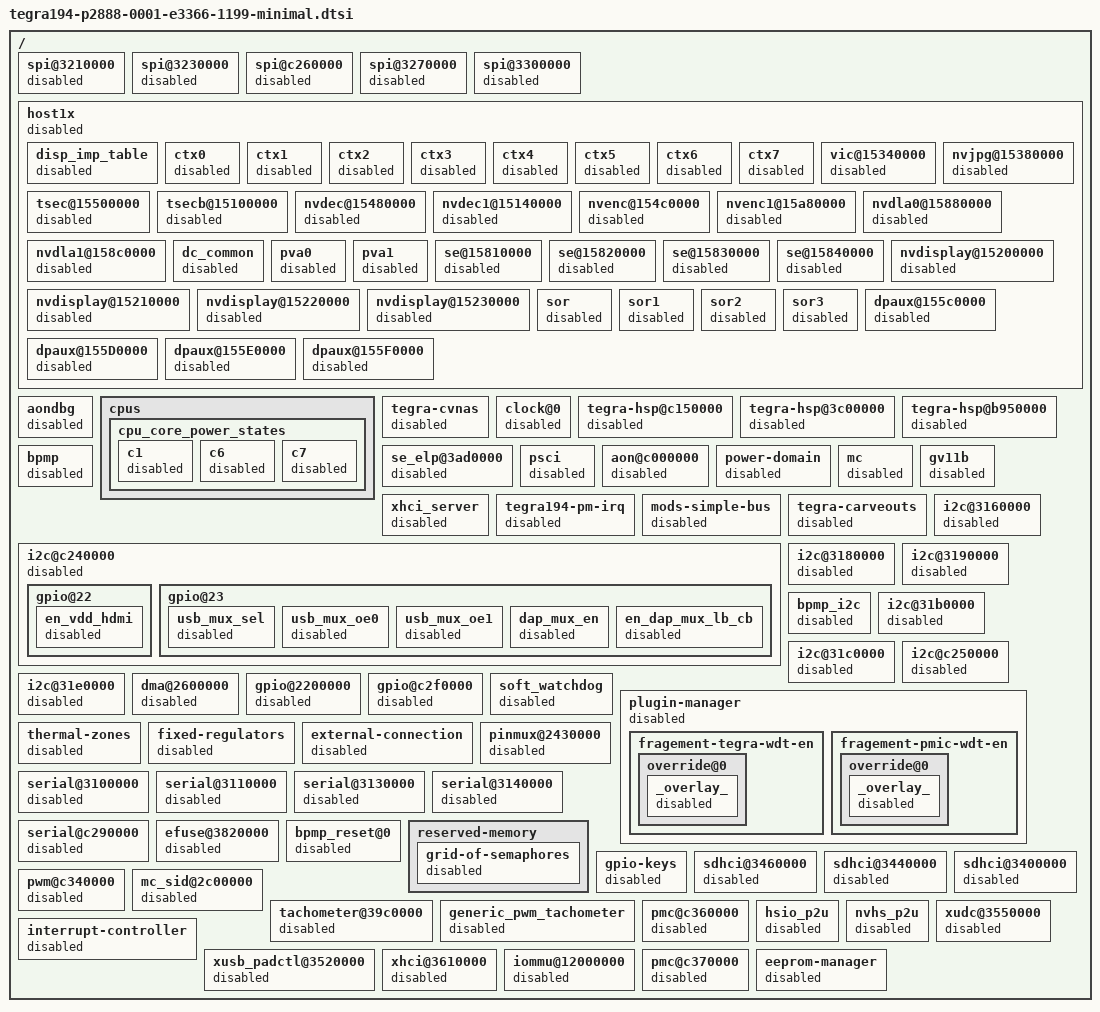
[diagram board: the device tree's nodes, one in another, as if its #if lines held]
/*
 * This override include file disables all the nodes that are not required for
 * boot to console. The nodes that are disabled here are for CVM:P2888-0001 and
 * CVB:E3366-1199 platforms.
 *
 * Copyright (c) 2017, NVIDIA CORPORATION.  All rights reserved.
 *
 * This program is free software; you can redistribute it and/or modify
 * it under the terms of the GNU General Public License as published by
 * the Free Software Foundation; version 2 of the License.
 *
 * This program is distributed in the hope that it will be useful, but WITHOUT
 * ANY WARRANTY; without even the implied warranty of MERCHANTABILITY or
 * FITNESS FOR A PARTICULAR PURPOSE.  See the GNU General Public License for
 * more details.
 */

/ {

	spi@3210000 {
		status = "disabled";
	};

	spi@3230000 {
		status = "disabled";
	};

	spi@c260000 {
		status = "disabled";
	};

	spi@3270000 {
		status = "disabled";
	};

	spi@3300000 {
		status = "disabled";
	};

	host1x {
		status = "disabled";

		disp_imp_table {
			status = "disabled";
		};

		ctx0 {
			status = "disabled";
		};

		ctx1 {
			status = "disabled";
		};

		ctx2 {
			status = "disabled";
		};

		ctx3 {
			status = "disabled";
		};

		ctx4 {
			status = "disabled";
		};

		ctx5 {
			status = "disabled";
		};

		ctx6 {
			status = "disabled";
		};

		ctx7 {
			status = "disabled";
		};

		vic@15340000 {
			status = "disabled";
		};

		nvjpg@15380000 {
			status = "disabled";
		};

		tsec@15500000 {
			status = "disabled";
		};

		tsecb@15100000 {
			status = "disabled";
		};

		nvdec@15480000 {
			status = "disabled";
		};

		nvdec1@15140000 {
			status = "disabled";
		};

		nvenc@154c0000 {
			status = "disabled";
		};

		nvenc1@15a80000 {
			status = "disabled";
		};

		nvdla0@15880000 {
			status = "disabled";
		};

		nvdla1@158c0000 {
			status = "disabled";
		};

		dc_common {
			status = "disabled";
		};

		pva0 {
			status = "disabled";
		};

		pva1 {
			status = "disabled";
		};

		se@15810000 {
			status = "disabled";
		};

		se@15820000 {
			status = "disabled";
		};

		se@15830000 {
			status = "disabled";
		};

		se@15840000 {
			status = "disabled";
		};

		nvdisplay@15200000 {
			status = "disabled";
		};

		nvdisplay@15210000 {
			status = "disabled";
		};

		nvdisplay@15220000 {
			status = "disabled";
		};

		nvdisplay@15230000 {
			status = "disabled";
		};

		sor {
			status = "disabled";
		};

		sor1 {
			status = "disabled";
		};

		sor2 {
			status = "disabled";
		};

		sor3 {
			status = "disabled";
		};

		dpaux@155c0000 {
			status = "disabled";
		};

		dpaux@155D0000 {
			status = "disabled";
		};

		dpaux@155E0000 {
			status = "disabled";
		};

		dpaux@155F0000 {
			status = "disabled";
		};
	};

	aondbg {
		status = "disabled";
	};

	cpus {
		cpu_core_power_states {

			c1 {
				status = "disabled";
			};

			c6 {
				status = "disabled";
			};

			c7 {
				status = "disabled";
			};
		};
	};

	tegra-cvnas {
		status = "disabled";
	};

	clock@0 {
		status = "disabled";
	};

	tegra-hsp@c150000 {
		status = "disabled";
	};

	tegra-hsp@3c00000 {
		status = "disabled";
	};

	tegra-hsp@b950000 {
		status = "disabled";
	};

	bpmp {
		status = "disabled";
	};

	se_elp@3ad0000 {
		status = "disabled";
	};

	psci {
		status = "disabled";
	};

	aon@c000000 {
		status = "disabled";
	};

	power-domain {
		status = "disabled";
	};

	mc {
		status = "disabled";
	};

	gv11b {
		status = "disabled";
	};

	xhci_server {
		status = "disabled";
	};

	tegra194-pm-irq {
		status = "disabled";
	};

	mods-simple-bus {
		status = "disabled";
	};

	tegra-carveouts {
		status = "disabled";
	};

	i2c@3160000 {
		status = "disabled";
	};

	i2c@c240000 {
		status = "disabled";

		gpio@22 {
			en_vdd_hdmi {
				status = "disabled";
			};
		};

		gpio@23 {
			usb_mux_sel {
				status = "disabled";
			};

			usb_mux_oe0 {
				status = "disabled";
			};

			usb_mux_oe1 {
				status = "disabled";
			};

			dap_mux_en {
				status = "disabled";
			};

			en_dap_mux_lb_cb {
				status = "disabled";
			};
		};
	};

	i2c@3180000 {
		status = "disabled";
	};

	i2c@3190000 {
		status = "disabled";
	};

	bpmp_i2c {
		status = "disabled";
	};

	i2c@31b0000 {
		status = "disabled";
	};

	i2c@31c0000 {
		status = "disabled";
	};

	i2c@c250000 {
		status = "disabled";
	};

	i2c@31e0000 {
		status = "disabled";
	};

	dma@2600000 {
		status = "disabled";
	};

	gpio@2200000 {
		status = "disabled";
	};

	gpio@c2f0000 {
		status = "disabled";
	};

	soft_watchdog {
		status = "disabled";
	};

	plugin-manager {
		status = "disabled";
	};

	thermal-zones {
		status = "disabled";
	};

	fixed-regulators {
		status = "disabled";
	};

	external-connection {
		status = "disabled";
	};

	pinmux@2430000 {
		status = "disabled";
	};

	serial@3100000 {
		status = "disabled";
	};

	serial@3110000 {
		status = "disabled";
	};

	serial@3130000 {
		status = "disabled";
	};

	serial@3140000 {
		status = "disabled";
	};

	serial@c290000 {
		status = "disabled";
	};

	efuse@3820000 {
		status = "disabled";
	};

	bpmp_reset@0 {
		status = "disabled";
	};

	reserved-memory {
		grid-of-semaphores {
			status = "disabled";
		};
	};

	plugin-manager {
		status = "disabled";

		fragement-tegra-wdt-en {

			override@0 {

				_overlay_ {
					status = "disabled";
				};
			};
		};

		fragement-pmic-wdt-en {

			override@0 {

				_overlay_ {
					status = "disabled";
				};
			};
		};
	};

	gpio-keys {
		status = "disabled";
	};

	sdhci@3460000 {
		status = "disabled";
	};

	sdhci@3440000 {
		status = "disabled";
	};

	sdhci@3400000 {
		status = "disabled";
	};

	pwm@c340000 {
		status = "disabled";
	};

	mc_sid@2c00000 {
		status = "disabled";
	};

	tachometer@39c0000 {
		status = "disabled";
	};

	generic_pwm_tachometer {
		status = "disabled";
	};

	pmc@c360000 {
		status = "disabled";
	};

	hsio_p2u {
		status = "disabled";
	};

	nvhs_p2u {
		status = "disabled";
	};

	interrupt-controller {
		status = "disabled";
	};

#if TEGRA_XUSB_PADCONTROL_VERSION >= DT_VERSION_2
	xusb_padctl@3520000 {
		status = "disabled";
	};
#endif

	xudc@3550000 {
		status = "disabled";
	};

	xhci@3610000 {
		status = "disabled";
	};

	iommu@12000000 {
		status = "disabled";
	};

	pmc@c370000 {
		status = "disabled";
	};

	eeprom-manager {
		status = "disabled";
	};

};
